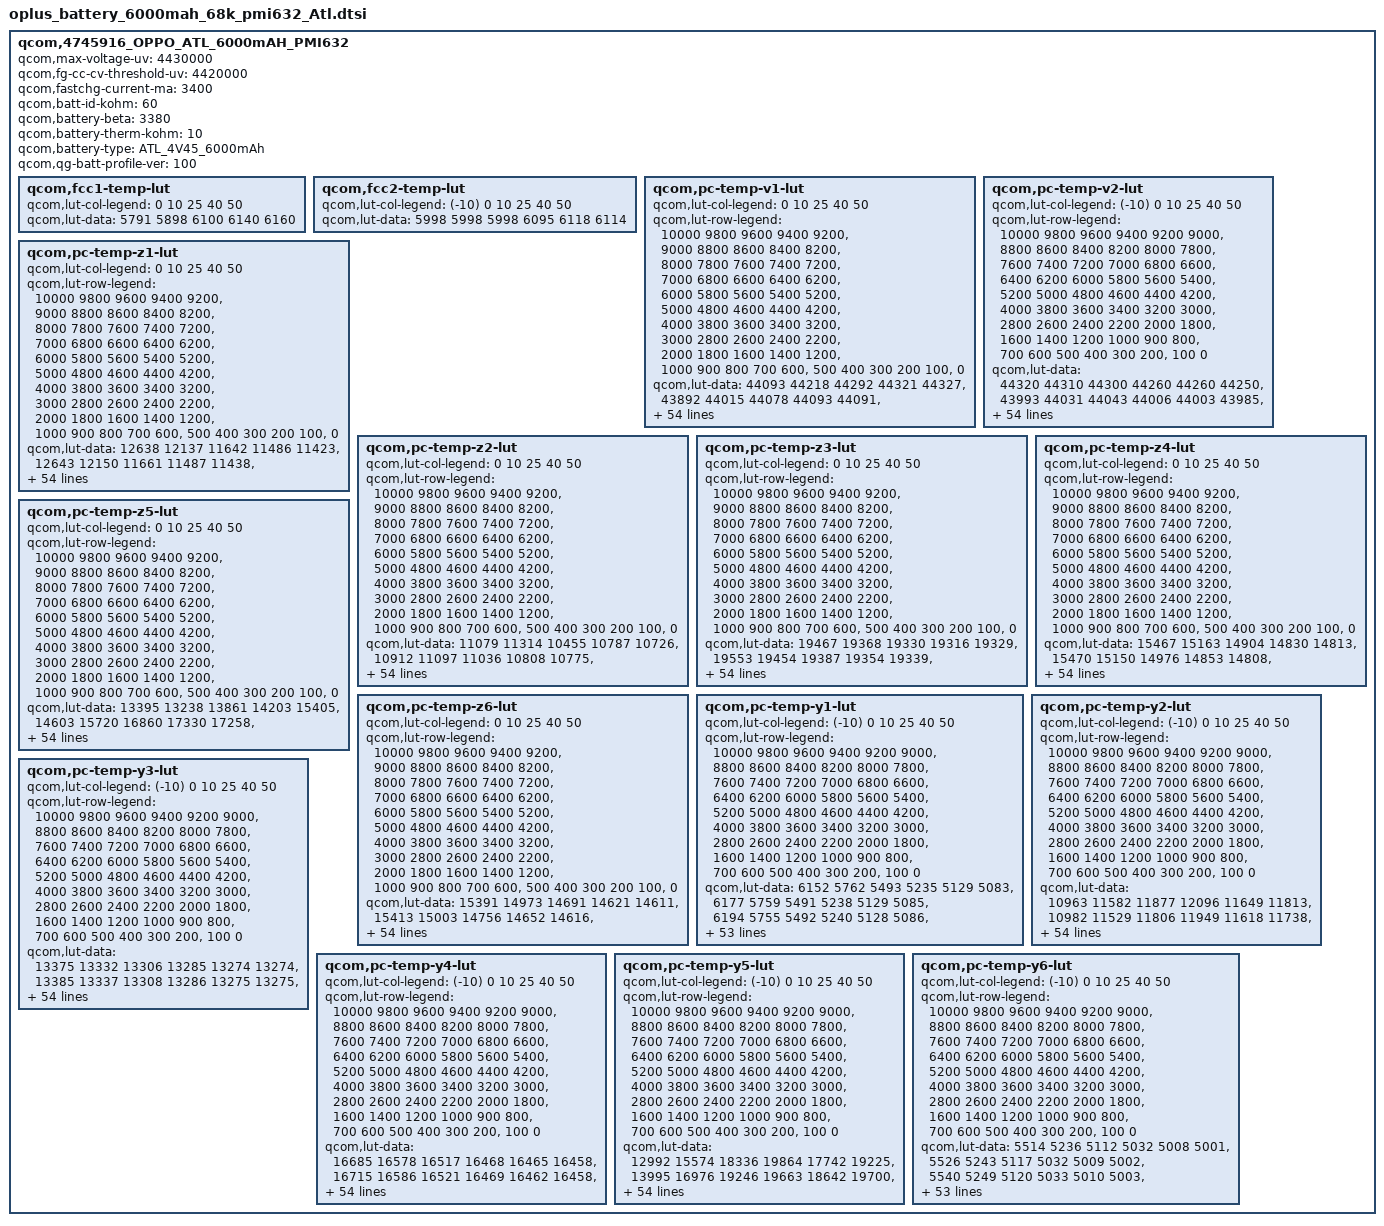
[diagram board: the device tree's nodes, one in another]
qcom,4745916_OPPO_ATL_6000mAH_PMI632 {
    /* 4745916_Wingtech_s88635_NVT_6000mAH_PMI632_averaged_MasterSlave_Aug20th2020 */
    qcom,max-voltage-uv = <4430000>;
    qcom,fg-cc-cv-threshold-uv = <4420000>;
    qcom,fastchg-current-ma = <3400>;
    //qcom,batt-id-kohm = <68>;
    qcom,batt-id-kohm = <60>;
    qcom,battery-beta = <3380>;
    qcom,battery-therm-kohm = <10>;
    qcom,battery-type = "ATL_4V45_6000mAh";
    qcom,qg-batt-profile-ver = <100>;
    //qcom,jeita-soft-thresholds_oppo = <0x5E68 0x72A>;
    //qcom,jeita-hard-thresholds_oppo = <0x5E68 0x72A>;

	qcom,fcc1-temp-lut {
		qcom,lut-col-legend = <0 10 25 40 50>;
		qcom,lut-data = <5791 5898 6100 6140 6160>;
	};

	qcom,fcc2-temp-lut {
		qcom,lut-col-legend = <(-10) 0 10 25 40 50>;
		qcom,lut-data = <5998 5998 5998 6095 6118 6114>;
	};

	qcom,pc-temp-v1-lut {
		qcom,lut-col-legend = <0 10 25 40 50>;
		qcom,lut-row-legend = <10000 9800 9600 9400 9200>,
			<9000 8800 8600 8400 8200>,
			<8000 7800 7600 7400 7200>,
			<7000 6800 6600 6400 6200>,
			<6000 5800 5600 5400 5200>,
			<5000 4800 4600 4400 4200>,
			<4000 3800 3600 3400 3200>,
			<3000 2800 2600 2400 2200>,
			<2000 1800 1600 1400 1200>,
			<1000 900 800 700 600>,
			<500 400 300 200 100>,
			<0>;
		qcom,lut-data = <44093 44218 44292 44321 44327>,
			<43892 44015 44078 44093 44091>,
			<43673 43805 43877 43887 43880>,
			<43445 43590 43671 43683 43676>,
			<43211 43368 43451 43467 43462>,
			<42968 43135 43218 43239 43236>,
			<42724 42893 42979 43005 43003>,
			<42482 42649 42733 42762 42763>,
			<42240 42403 42482 42513 42516>,
			<42002 42158 42233 42266 42270>,
			<41770 41919 41985 42018 42025>,
			<41542 41683 41741 41774 41782>,
			<41321 41454 41502 41535 41541>,
			<41107 41231 41269 41300 41303>,
			<40897 41014 41044 41073 41073>,
			<40690 40803 40826 40852 40849>,
			<40489 40598 40618 40640 40636>,
			<40299 40403 40417 40436 40434>,
			<40116 40224 40226 40242 40243>,
			<39942 40050 40054 40062 40063>,
			<39785 39870 39884 39894 39895>,
			<39629 39688 39659 39688 39695>,
			<39437 39491 39352 39396 39404>,
			<39188 39235 39101 39133 39131>,
			<38968 38968 38955 38982 38983>,
			<38822 38813 38842 38869 38879>,
			<38706 38725 38737 38761 38774>,
			<38621 38651 38642 38657 38665>,
			<38559 38572 38553 38561 38560>,
			<38507 38497 38470 38466 38460>,
			<38454 38427 38393 38377 38367>,
			<38404 38356 38321 38298 38285>,
			<38355 38293 38253 38227 38212>,
			<38306 38239 38192 38160 38143>,
			<38260 38192 38139 38096 38074>,
			<38218 38148 38089 38036 38008>,
			<38181 38111 38042 37980 37942>,
			<38138 38071 37998 37928 37880>,
			<38082 38017 37939 37863 37805>,
			<38012 37948 37852 37770 37705>,
			<37925 37864 37748 37661 37590>,
			<37806 37754 37634 37548 37472>,
			<37675 37626 37501 37422 37343>,
			<37532 37478 37339 37266 37189>,
			<37371 37317 37186 37122 37052>,
			<37223 37172 37081 37030 36968>,
			<37168 37121 37054 36997 36936>,
			<37124 37084 37031 36977 36916>,
			<37086 37062 37011 36953 36890>,
			<37046 37031 36956 36891 36808>,
			<36984 36990 36705 36630 36503>,
			<36791 36863 36250 36186 36045>,
			<35940 36433 35636 35600 35444>,
			<31626 35692 34766 34796 34617>,
			<30632 33115 33297 33531 33304>,
			<30000 30000 30000 30000 30000>;
	};

	qcom,pc-temp-v2-lut {
		qcom,lut-col-legend = <(-10) 0 10 25 40 50>;
		qcom,lut-row-legend = <10000 9800 9600 9400 9200 9000>,
			<8800 8600 8400 8200 8000 7800>,
			<7600 7400 7200 7000 6800 6600>,
			<6400 6200 6000 5800 5600 5400>,
			<5200 5000 4800 4600 4400 4200>,
			<4000 3800 3600 3400 3200 3000>,
			<2800 2600 2400 2200 2000 1800>,
			<1600 1400 1200 1000 900 800>,
			<700 600 500 400 300 200>,
			<100 0>;
		qcom,lut-data = <44320 44310 44300 44260 44260 44250>,
			<43993 44031 44043 44006 44003 43985>,
			<43694 43770 43799 43761 43757 43732>,
			<43429 43528 43568 43526 43524 43496>,
			<43196 43308 43352 43304 43305 43276>,
			<42965 43085 43132 43075 43079 43051>,
			<42719 42843 42893 42830 42839 42811>,
			<42470 42595 42646 42581 42592 42566>,
			<42223 42348 42399 42332 42345 42319>,
			<41979 42100 42152 42084 42095 42070>,
			<41733 41857 41907 41838 41848 41824>,
			<41478 41618 41665 41595 41605 41581>,
			<41227 41385 41428 41356 41365 41342>,
			<41013 41162 41196 41122 41131 41109>,
			<40837 40949 40971 40893 40903 40882>,
			<40634 40739 40753 40674 40683 40663>,
			<40326 40530 40541 40463 40473 40450>,
			<39977 40319 40334 40261 40270 40247>,
			<39711 40086 40138 40074 40083 40060>,
			<39499 39824 39956 39895 39902 39882>,
			<39303 39571 39756 39689 39699 39683>,
			<39112 39336 39502 39432 39467 39454>,
			<38930 39117 39232 39181 39237 39228>,
			<38755 38928 39016 38977 39024 39019>,
			<38583 38762 38836 38797 38826 38825>,
			<38435 38612 38681 38649 38672 38672>,
			<38316 38476 38549 38527 38550 38549>,
			<38216 38352 38433 38419 38441 38439>,
			<38134 38242 38325 38317 38340 38336>,
			<38067 38141 38224 38223 38246 38242>,
			<38006 38054 38133 38137 38163 38157>,
			<37948 37976 38049 38060 38088 38081>,
			<37893 37909 37973 37987 38016 38007>,
			<37836 37859 37906 37922 37949 37938>,
			<37779 37824 37848 37859 37880 37865>,
			<37720 37788 37796 37790 37796 37770>,
			<37657 37751 37752 37717 37698 37652>,
			<37592 37711 37712 37641 37600 37543>,
			<37518 37663 37659 37563 37507 37449>,
			<37437 37605 37593 37482 37415 37359>,
			<37348 37529 37515 37394 37331 37274>,
			<37246 37403 37421 37298 37245 37188>,
			<37137 37250 37306 37175 37117 37058>,
			<37028 37099 37168 37037 36982 36925>,
			<36919 36938 37010 36914 36877 36819>,
			<36808 36796 36864 36863 36831 36782>,
			<36754 36748 36818 36841 36819 36769>,
			<36695 36702 36776 36821 36803 36749>,
			<36610 36656 36745 36782 36767 36711>,
			<37099 36596 36686 36658 36646 36565>,
			<37944 36535 36601 36320 36286 36193>,
			<37349 36786 36419 35770 35760 35658>,
			<31698 37119 36004 35009 35060 34955>,
			<30995 31207 35383 33808 34062 33935>,
			<30139 30334 33146 32016 32441 32316>,
			<29008 29322 29643 27350 29483 27639>;
	};

	qcom,pc-temp-z1-lut {
		qcom,lut-col-legend = <0 10 25 40 50>;
		qcom,lut-row-legend = <10000 9800 9600 9400 9200>,
			<9000 8800 8600 8400 8200>,
			<8000 7800 7600 7400 7200>,
			<7000 6800 6600 6400 6200>,
			<6000 5800 5600 5400 5200>,
			<5000 4800 4600 4400 4200>,
			<4000 3800 3600 3400 3200>,
			<3000 2800 2600 2400 2200>,
			<2000 1800 1600 1400 1200>,
			<1000 900 800 700 600>,
			<500 400 300 200 100>,
			<0>;
		qcom,lut-data = <12638 12137 11642 11486 11423>,
			<12643 12150 11661 11487 11438>,
			<12649 12152 11669 11487 11437>,
			<12655 12147 11676 11488 11437>,
			<12654 12141 11675 11488 11437>,
			<12643 12136 11670 11487 11438>,
			<12636 12129 11668 11486 11439>,
			<12638 12123 11669 11487 11440>,
			<12640 12117 11669 11488 11444>,
			<12637 12111 11668 11490 11448>,
			<12629 12108 11663 11492 11453>,
			<12621 12106 11662 11494 11458>,
			<12614 12103 11665 11498 11463>,
			<12601 12101 11669 11501 11468>,
			<12592 12098 11672 11505 11472>,
			<12579 12097 11675 11509 11477>,
			<12565 12099 11679 11514 11481>,
			<12559 12101 11684 11518 11486>,
			<12556 12100 11688 11522 11490>,
			<12554 12099 11692 11527 11495>,
			<12550 12099 11696 11531 11501>,
			<12544 12100 11699 11534 11505>,
			<12544 12102 11704 11537 11508>,
			<12551 12106 11708 11539 11511>,
			<12557 12112 11713 11542 11514>,
			<12560 12118 11718 11546 11517>,
			<12565 12126 11723 11550 11521>,
			<12568 12131 11728 11553 11525>,
			<12571 12132 11733 11557 11529>,
			<12573 12132 11737 11561 11533>,
			<12574 12133 11741 11565 11536>,
			<12574 12136 11745 11569 11540>,
			<12575 12140 11750 11573 11543>,
			<12583 12142 11754 11577 11547>,
			<12593 12144 11759 11580 11551>,
			<12598 12147 11764 11583 11554>,
			<12602 12149 11767 11586 11557>,
			<12607 12152 11769 11590 11560>,
			<12615 12157 11772 11593 11562>,
			<12626 12166 11779 11595 11564>,
			<12633 12175 11785 11598 11566>,
			<12642 12184 11789 11601 11568>,
			<12650 12195 11793 11603 11571>,
			<12666 12210 11802 11606 11573>,
			<12694 12213 11808 11611 11575>,
			<12676 12210 11814 11613 11577>,
			<12680 12222 11814 11613 11577>,
			<12677 12213 11815 11614 11578>,
			<12682 12209 11823 11616 11580>,
			<12683 12218 11827 11619 11582>,
			<12682 12220 11830 11625 11586>,
			<12701 12226 11838 11629 11591>,
			<12718 12232 11851 11638 11598>,
			<12694 12237 11869 11650 11608>,
			<12694 12237 11869 11650 11608>,
			<12694 12237 11869 11650 11608>;
	};

	qcom,pc-temp-z2-lut {
		qcom,lut-col-legend = <0 10 25 40 50>;
		qcom,lut-row-legend = <10000 9800 9600 9400 9200>,
			<9000 8800 8600 8400 8200>,
			<8000 7800 7600 7400 7200>,
			<7000 6800 6600 6400 6200>,
			<6000 5800 5600 5400 5200>,
			<5000 4800 4600 4400 4200>,
			<4000 3800 3600 3400 3200>,
			<3000 2800 2600 2400 2200>,
			<2000 1800 1600 1400 1200>,
			<1000 900 800 700 600>,
			<500 400 300 200 100>,
			<0>;
		qcom,lut-data = <11079 11314 10455 10787 10726>,
			<10912 11097 11036 10808 10775>,
			<10839 10992 11013 10937 10981>,
			<10788 10953 10982 10984 11019>,
			<10749 10926 10969 10987 11025>,
			<10716 10895 10950 10952 10985>,
			<10695 10865 10929 10910 10931>,
			<10684 10848 10898 10879 10893>,
			<10677 10838 10864 10851 10860>,
			<10676 10832 10836 10829 10821>,
			<10680 10833 10810 10810 10768>,
			<10686 10835 10805 10801 10737>,
			<10696 10840 10829 10814 10765>,
			<10713 10856 10860 10836 10825>,
			<10730 10882 10884 10854 10874>,
			<10745 10911 10908 10878 10920>,
			<10762 10949 10935 10906 10947>,
			<10793 10983 10971 10944 10957>,
			<10842 11014 11001 10981 10964>,
			<10889 11038 11016 11004 10965>,
			<10932 11038 11028 11020 10964>,
			<10966 11017 11067 11068 11004>,
			<10972 11003 11187 11335 11407>,
			<10968 11015 11258 11560 11806>,
			<10966 11037 11171 11408 11634>,
			<10966 11043 11043 11083 11146>,
			<10967 11041 11033 11019 11021>,
			<10969 11040 11081 11164 11335>,
			<10976 11047 11115 11277 11594>,
			<10985 11061 11126 11291 11527>,
			<10994 11065 11134 11291 11365>,
			<11006 11061 11139 11259 11223>,
			<11015 11057 11140 11153 11064>,
			<11021 11058 11138 11082 10982>,
			<11026 11063 11115 11066 10979>,
			<11033 11069 11093 11063 10984>,
			<11040 11077 11111 11095 11024>,
			<11048 11088 11171 11188 11163>,
			<11061 11103 11218 11277 11295>,
			<11077 11122 11252 11364 11416>,
			<11095 11140 11275 11422 11498>,
			<11117 11155 11285 11407 11485>,
			<11148 11176 11290 11368 11439>,
			<11212 11217 11296 11349 11411>,
			<11135 11538 11352 11347 11364>,
			<10997 11715 11414 11189 11111>,
			<10996 11726 11374 11195 11105>,
			<10840 11729 11350 11207 11141>,
			<10694 12189 11466 11192 11255>,
			<10433 12217 11742 11381 11268>,
			<10456 12182 11709 11241 11024>,
			<10308 11894 11417 10934 10748>,
			<11440 11516 11215 10804 10662>,
			<11525 11230 11003 10661 10586>,
			<11525 11230 11003 10661 10586>,
			<11525 11230 11003 10661 10586>;
	};

	qcom,pc-temp-z3-lut {
		qcom,lut-col-legend = <0 10 25 40 50>;
		qcom,lut-row-legend = <10000 9800 9600 9400 9200>,
			<9000 8800 8600 8400 8200>,
			<8000 7800 7600 7400 7200>,
			<7000 6800 6600 6400 6200>,
			<6000 5800 5600 5400 5200>,
			<5000 4800 4600 4400 4200>,
			<4000 3800 3600 3400 3200>,
			<3000 2800 2600 2400 2200>,
			<2000 1800 1600 1400 1200>,
			<1000 900 800 700 600>,
			<500 400 300 200 100>,
			<0>;
		qcom,lut-data = <19467 19368 19330 19316 19329>,
			<19553 19454 19387 19354 19339>,
			<19611 19498 19404 19373 19363>,
			<19652 19519 19415 19383 19373>,
			<19674 19530 19426 19393 19381>,
			<19689 19533 19436 19402 19389>,
			<19695 19535 19441 19407 19395>,
			<19694 19535 19442 19408 19396>,
			<19691 19534 19443 19409 19397>,
			<19689 19533 19442 19409 19397>,
			<19687 19531 19440 19408 19394>,
			<19685 19528 19437 19406 19391>,
			<19680 19524 19432 19400 19388>,
			<19672 19520 19426 19392 19385>,
			<19669 19516 19420 19387 19382>,
			<19671 19512 19414 19382 19379>,
			<19674 19509 19409 19378 19375>,
			<19669 19505 19404 19374 19369>,
			<19650 19498 19399 19370 19361>,
			<19639 19492 19394 19363 19353>,
			<19637 19492 19390 19355 19345>,
			<19637 19498 19393 19354 19343>,
			<19640 19506 19415 19368 19354>,
			<19657 19516 19429 19381 19365>,
			<19671 19526 19418 19370 19356>,
			<19669 19526 19399 19347 19332>,
			<19663 19513 19393 19341 19325>,
			<19656 19501 19389 19342 19342>,
			<19649 19501 19388 19343 19358>,
			<19641 19500 19391 19356 19368>,
			<19637 19501 19397 19375 19379>,
			<19633 19507 19404 19379 19380>,
			<19630 19513 19413 19378 19373>,
			<19628 19512 19416 19376 19365>,
			<19627 19508 19414 19372 19356>,
			<19625 19505 19410 19366 19348>,
			<19623 19503 19406 19359 19341>,
			<19620 19500 19400 19351 19336>,
			<19614 19496 19396 19348 19334>,
			<19606 19492 19393 19350 19335>,
			<19597 19486 19390 19351 19336>,
			<19586 19480 19388 19351 19340>,
			<19559 19472 19385 19351 19346>,
			<19438 19460 19380 19352 19349>,
			<19324 19418 19370 19351 19348>,
			<19298 19398 19362 19332 19329>,
			<19296 19393 19351 19330 19324>,
			<19294 19389 19350 19323 19315>,
			<19289 19285 19330 19318 19309>,
			<19277 19280 19306 19311 19313>,
			<19277 19279 19316 19343 19336>,
			<19296 19285 19330 19357 19343>,
			<19456 19358 19357 19357 19343>,
			<19285 19425 19378 19354 19343>,
			<19285 19425 19378 19354 19343>,
			<19285 19425 19378 19354 19343>;
	};

	qcom,pc-temp-z4-lut {
		qcom,lut-col-legend = <0 10 25 40 50>;
		qcom,lut-row-legend = <10000 9800 9600 9400 9200>,
			<9000 8800 8600 8400 8200>,
			<8000 7800 7600 7400 7200>,
			<7000 6800 6600 6400 6200>,
			<6000 5800 5600 5400 5200>,
			<5000 4800 4600 4400 4200>,
			<4000 3800 3600 3400 3200>,
			<3000 2800 2600 2400 2200>,
			<2000 1800 1600 1400 1200>,
			<1000 900 800 700 600>,
			<500 400 300 200 100>,
			<0>;
		qcom,lut-data = <15467 15163 14904 14830 14813>,
			<15470 15150 14976 14853 14808>,
			<15399 15124 14955 14856 14827>,
			<15293 15069 14921 14837 14813>,
			<15210 15006 14890 14818 14797>,
			<15133 14962 14858 14797 14780>,
			<15070 14925 14831 14777 14763>,
			<15023 14893 14808 14761 14748>,
			<14984 14865 14787 14746 14735>,
			<14949 14841 14769 14732 14722>,
			<14918 14821 14753 14718 14711>,
			<14892 14804 14739 14707 14701>,
			<14872 14789 14724 14700 14693>,
			<14856 14775 14713 14694 14685>,
			<14839 14763 14708 14689 14680>,
			<14817 14751 14704 14684 14676>,
			<14801 14740 14701 14679 14672>,
			<14800 14733 14698 14674 14670>,
			<14801 14731 14695 14670 14667>,
			<14801 14729 14691 14669 14665>,
			<14781 14727 14689 14668 14662>,
			<14752 14724 14696 14671 14663>,
			<14751 14723 14739 14713 14707>,
			<14782 14753 14776 14759 14758>,
			<14812 14806 14793 14778 14774>,
			<14827 14819 14804 14791 14783>,
			<14838 14815 14804 14793 14782>,
			<14840 14810 14796 14782 14755>,
			<14832 14801 14785 14766 14724>,
			<14821 14787 14771 14741 14702>,
			<14811 14773 14753 14711 14681>,
			<14800 14759 14735 14695 14672>,
			<14790 14747 14715 14683 14667>,
			<14781 14739 14705 14678 14666>,
			<14772 14734 14700 14677 14666>,
			<14764 14729 14698 14677 14668>,
			<14756 14724 14697 14677 14668>,
			<14749 14719 14697 14678 14667>,
			<14740 14715 14697 14679 14668>,
			<14730 14711 14701 14684 14675>,
			<14721 14706 14705 14690 14684>,
			<14711 14698 14702 14688 14680>,
			<14715 14690 14694 14681 14669>,
			<14812 14680 14690 14679 14666>,
			<14847 14670 14679 14669 14659>,
			<14855 14670 14659 14661 14651>,
			<14854 14672 14659 14658 14649>,
			<14854 14672 14648 14651 14644>,
			<14855 14781 14658 14638 14631>,
			<14860 14781 14680 14638 14620>,
			<14860 14780 14690 14631 14634>,
			<14852 14776 14684 14632 14640>,
			<14832 14720 14658 14636 14646>,
			<16713 14703 14646 14644 14652>,
			<16713 14703 14646 14644 14652>,
			<16713 14703 14646 14644 14652>;
	};

	qcom,pc-temp-z5-lut {
		qcom,lut-col-legend = <0 10 25 40 50>;
		qcom,lut-row-legend = <10000 9800 9600 9400 9200>,
			<9000 8800 8600 8400 8200>,
			<8000 7800 7600 7400 7200>,
			<7000 6800 6600 6400 6200>,
			<6000 5800 5600 5400 5200>,
			<5000 4800 4600 4400 4200>,
			<4000 3800 3600 3400 3200>,
			<3000 2800 2600 2400 2200>,
			<2000 1800 1600 1400 1200>,
			<1000 900 800 700 600>,
			<500 400 300 200 100>,
			<0>;
		qcom,lut-data = <13395 13238 13861 14203 15405>,
			<14603 15720 16860 17330 17258>,
			<15697 17156 17659 18995 19934>,
			<16676 17930 18195 20073 21256>,
			<17463 18451 18832 21096 22496>,
			<18133 18801 19577 22097 23858>,
			<18694 19048 20100 22951 25074>,
			<19126 19357 20485 23585 26028>,
			<19519 19807 20889 24144 26833>,
			<20041 20319 21370 24908 27489>,
			<20805 20839 21991 25969 27958>,
			<21586 21428 22715 26757 28560>,
			<22180 22057 23712 27146 29998>,
			<22759 22692 24509 27332 32129>,
			<23711 23444 24824 27452 34093>,
			<26440 24706 25006 27990 36186>,
			<28995 26818 25086 28602 37131>,
			<28928 27926 25375 29793 36255>,
			<27743 27434 25714 30841 34933>,
			<27089 26696 25976 30445 34032>,
			<29132 27288 26390 29216 32665>,
			<33704 31904 30026 29518 32725>,
			<40692 37395 46948 38994 39701>,
			<54752 42852 57567 47391 46680>,
			<64253 47922 47159 40420 40639>,
			<61632 47859 30947 25257 24512>,
			<54918 39111 25763 20274 19359>,
			<49498 31673 23567 19330 21016>,
			<44938 30722 22852 18974 23281>,
			<41762 30248 23317 21053 27230>,
			<40954 30432 24344 25068 32746>,
			<40532 33752 26595 27739 34461>,
			<40413 37670 31386 29907 34469>,
			<41403 39728 35195 31670 34043>,
			<43031 41290 38148 33375 33138>,
			<44202 42176 40054 34615 32085>,
			<45269 42918 39899 34106 31599>,
			<45910 43432 38993 31946 31302>,
			<45984 43291 38022 31012 31098>,
			<45794 42650 36301 31461 30906>,
			<45232 41985 34257 31927 30820>,
			<43008 40319 32217 30631 31220>,
			<38545 38285 30148 28096 32441>,
			<25627 35924 28581 28875 35251>,
			<15587 31317 28570 30192 37060>,
			<13431 27931 29987 24301 26494>,
			<13337 26072 25427 23337 23690>,
			<13179 25568 26406 21923 21712>,
			<12935 13141 19869 23523 23900>,
			<12696 12915 15762 21518 29288>,
			<12682 12861 16286 35648 36550>,
			<13902 13323 16850 36187 33343>,
			<27073 20549 21459 32062 28593>,
			<11344 29268 27669 25459 23605>,
			<11344 29268 27669 25459 23605>,
			<11344 29268 27669 25459 23605>;
	};

	qcom,pc-temp-z6-lut {
		qcom,lut-col-legend = <0 10 25 40 50>;
		qcom,lut-row-legend = <10000 9800 9600 9400 9200>,
			<9000 8800 8600 8400 8200>,
			<8000 7800 7600 7400 7200>,
			<7000 6800 6600 6400 6200>,
			<6000 5800 5600 5400 5200>,
			<5000 4800 4600 4400 4200>,
			<4000 3800 3600 3400 3200>,
			<3000 2800 2600 2400 2200>,
			<2000 1800 1600 1400 1200>,
			<1000 900 800 700 600>,
			<500 400 300 200 100>,
			<0>;
		qcom,lut-data = <15391 14973 14691 14621 14611>,
			<15413 15003 14756 14652 14616>,
			<15392 15009 14753 14658 14633>,
			<15357 14990 14747 14658 14634>,
			<15324 14964 14740 14657 14634>,
			<15287 14943 14731 14653 14631>,
			<15252 14923 14721 14647 14627>,
			<15223 14905 14712 14642 14623>,
			<15197 14889 14702 14636 14619>,
			<15174 14874 14694 14630 14614>,
			<15154 14862 14686 14625 14609>,
			<15137 14850 14678 14619 14604>,
			<15120 14840 14669 14613 14599>,
			<15104 14830 14661 14607 14595>,
			<15091 14821 14656 14602 14591>,
			<15080 14813 14652 14598 14588>,
			<15070 14806 14648 14594 14585>,
			<15059 14800 14644 14590 14581>,
			<15050 14795 14641 14587 14576>,
			<15040 14792 14637 14583 14572>,
			<15027 14791 14635 14579 14567>,
			<15016 14794 14640 14580 14566>,
			<15018 14798 14674 14608 14593>,
			<15042 14818 14695 14634 14621>,
			<15062 14847 14694 14633 14621>,
			<15067 14853 14693 14630 14615>,
			<15070 14847 14691 14627 14610>,
			<15070 14840 14686 14623 14607>,
			<15064 14835 14682 14619 14605>,
			<15056 14830 14678 14616 14602>,
			<15050 14826 14675 14613 14599>,
			<15044 14824 14672 14610 14596>,
			<15040 14822 14669 14605 14591>,
			<15036 14820 14666 14602 14586>,
			<15033 14817 14664 14599 14583>,
			<15030 14814 14662 14597 14579>,
			<15029 14812 14659 14594 14576>,
			<15027 14810 14657 14590 14573>,
			<15026 14809 14656 14589 14572>,
			<15025 14808 14657 14592 14576>,
			<15023 14807 14659 14595 14580>,
			<15021 14804 14657 14594 14580>,
			<15017 14800 14654 14592 14579>,
			<15009 14794 14651 14592 14579>,
			<14976 14774 14643 14588 14576>,
			<14969 14767 14633 14575 14563>,
			<14968 14766 14628 14573 14560>,
			<14967 14763 14623 14566 14553>,
			<14967 14758 14616 14558 14544>,
			<14967 14756 14616 14554 14542>,
			<14972 14757 14627 14569 14561>,
			<14985 14763 14635 14579 14569>,
			<15069 14781 14641 14582 14574>,
			<15803 14814 14653 14588 14580>,
			<15803 14814 14653 14588 14580>,
			<15803 14814 14653 14588 14580>;
	};

	qcom,pc-temp-y1-lut {
		qcom,lut-col-legend = <(-10) 0 10 25 40 50>;
		qcom,lut-row-legend = <10000 9800 9600 9400 9200 9000>,
			<8800 8600 8400 8200 8000 7800>,
			<7600 7400 7200 7000 6800 6600>,
			<6400 6200 6000 5800 5600 5400>,
			<5200 5000 4800 4600 4400 4200>,
			<4000 3800 3600 3400 3200 3000>,
			<2800 2600 2400 2200 2000 1800>,
			<1600 1400 1200 1000 900 800>,
			<700 600 500 400 300 200>,
			<100 0>;
		qcom,lut-data = <6152 5762 5493 5235 5129 5083>,
			<6177 5759 5491 5238 5129 5085>,
			<6194 5755 5492 5240 5128 5086>,
			<6205 5751 5492 5241 5128 5088>,
			<6212 5748 5493 5241 5128 5090>,
			<6216 5746 5494 5241 5128 5091>,
			<6215 5746 5496 5239 5128 5093>,
			<6210 5747 5499 5237 5128 5095>,
			<6207 5748 5498 5238 5128 5097>,
			<6197 5749 5492 5240 5129 5100>,
			<6190 5750 5488 5242 5129 5102>,
			<6195 5750 5488 5242 5130 5103>,
			<6202 5751 5488 5242 5130 5104>,
			<6208 5752 5489 5243 5131 5105>,
			<6211 5755 5491 5245 5132 5108>,
			<6215 5757 5492 5246 5133 5111>,
			<6222 5757 5491 5248 5135 5113>,
			<6229 5757 5488 5251 5137 5116>,
			<6230 5758 5489 5254 5139 5117>,
			<6225 5761 5492 5257 5141 5119>,
			<6221 5764 5494 5259 5143 5121>,
			<6219 5768 5495 5262 5144 5122>,
			<6221 5774 5495 5264 5146 5124>,
			<6227 5776 5496 5267 5148 5125>,
			<6239 5776 5497 5269 5150 5127>,
			<6246 5777 5498 5272 5152 5129>,
			<6239 5778 5503 5274 5153 5131>,
			<6225 5781 5509 5275 5154 5133>,
			<6217 5782 5510 5277 5157 5135>,
			<6211 5785 5509 5279 5160 5136>,
			<6207 5786 5508 5281 5162 5138>,
			<6212 5786 5509 5286 5164 5141>,
			<6219 5786 5510 5291 5166 5143>,
			<6219 5784 5511 5295 5169 5144>,
			<6212 5778 5513 5298 5171 5145>,
			<6210 5774 5515 5298 5172 5146>,
			<6214 5776 5518 5298 5172 5149>,
			<6218 5781 5523 5298 5172 5151>,
			<6216 5780 5525 5298 5174 5151>,
			<6201 5775 5527 5299 5175 5150>,
			<6191 5771 5527 5300 5176 5151>,
			<6202 5776 5528 5302 5177 5152>,
			<6214 5782 5529 5305 5178 5154>,
			<6211 5784 5530 5308 5180 5155>,
			<6220 5786 5529 5312 5181 5157>,
			<6233 5790 5533 5314 5185 5158>,
			<6227 5795 5544 5313 5184 5159>,
			<6233 5794 5538 5315 5184 5160>,
			<6275 5804 5547 5317 5185 5160>,
			<6256 5812 5546 5318 5185 5161>,
			<6310 5815 5557 5322 5187 5161>,
			<6334 5840 5546 5334 5191 5165>,
			<6421 5877 5568 5349 5196 5171>,
			<6448 5927 5593 5374 5206 5179>,
			<6448 5927 5593 5374 5206 5179>,
			<6448 5927 5593 5374 5206 5179>;
	};

	qcom,pc-temp-y2-lut {
		qcom,lut-col-legend = <(-10) 0 10 25 40 50>;
		qcom,lut-row-legend = <10000 9800 9600 9400 9200 9000>,
			<8800 8600 8400 8200 8000 7800>,
			<7600 7400 7200 7000 6800 6600>,
			<6400 6200 6000 5800 5600 5400>,
			<5200 5000 4800 4600 4400 4200>,
			<4000 3800 3600 3400 3200 3000>,
			<2800 2600 2400 2200 2000 1800>,
			<1600 1400 1200 1000 900 800>,
			<700 600 500 400 300 200>,
			<100 0>;
		qcom,lut-data = <10963 11582 11877 12096 11649 11813>,
			<10982 11529 11806 11949 11618 11738>,
			<11007 11479 11735 11817 11563 11647>,
			<11032 11433 11668 11706 11502 11553>,
			<11051 11391 11610 11624 11452 11470>,
			<11059 11356 11566 11577 11432 11412>,
			<11056 11323 11534 11567 11430 11361>,
			<11051 11298 11508 11575 11428 11322>,
			<11053 11289 11487 11567 11409 11312>,
			<11070 11285 11465 11535 11351 11288>,
			<11091 11283 11454 11519 11319 11268>,
			<11111 11297 11461 11501 11320 11247>,
			<11134 11324 11474 11483 11330 11231>,
			<11174 11346 11487 11499 11339 11253>,
			<11249 11367 11502 11542 11355 11316>,
			<11291 11389 11524 11587 11381 11350>,
			<11289 11421 11570 11630 11435 11344>,
			<11285 11453 11628 11677 11501 11340>,
			<11233 11461 11662 11734 11560 11382>,
			<10976 11461 11684 11797 11621 11475>,
			<10812 11463 11699 11824 11712 11589>,
			<11000 11510 11708 11829 11875 11771>,
			<11287 11589 11716 11835 11977 11903>,
			<11278 11632 11731 11857 11910 11928>,
			<10920 11656 11764 11892 11792 11931>,
			<10649 11682 11799 11918 11776 11923>,
			<10324 11728 11832 11945 11819 11881>,
			<9871 11775 11866 11970 11867 11865>,
			<9760 11784 11890 11989 11898 11964>,
			<9743 11781 11910 12006 11930 12099>,
			<9731 11780 11921 12026 11990 12139>,
			<9719 11854 11922 12077 12091 12156>,
			<9709 11965 11920 12107 12158 12178>,
			<9701 11957 11920 12086 12195 12231>,
			<9693 11784 11919 12053 12220 12279>,
			<9687 11620 11914 12041 12203 12247>,
			<9683 11541 11895 12035 12136 12115>,
			<9680 11476 11862 12027 12076 12006>,
			<9676 11402 11822 11978 11998 11912>,
			<9673 11326 11764 11915 11933 11848>,
			<9671 11199 11694 11899 11934 11886>,
			<9670 10500 11606 11905 11949 11969>,
			<9669 9820 11507 11897 11919 11918>,
			<9667 9735 11410 11874 11850 11767>,
			<9666 9699 11277 11833 11721 11628>,
			<9664 9683 11143 11687 11541 11474>,
			<9668 9676 11013 11641 11529 11401>,
			<9696 9671 10168 11598 11554 11483>,
			<9781 9666 10331 11591 11566 11552>,
			<9666 9663 9974 11574 11519 11428>,
			<9657 9706 9737 11483 11462 11304>,
			<9652 9677 9673 11301 11345 11222>,
			<9654 9660 9684 11060 11216 11148>,
			<9652 9656 9884 10528 11030 10893>,
			<9652 9656 9884 10528 11030 10893>,
			<9652 9656 9884 10528 11030 10893>;
	};

	qcom,pc-temp-y3-lut {
		qcom,lut-col-legend = <(-10) 0 10 25 40 50>;
		qcom,lut-row-legend = <10000 9800 9600 9400 9200 9000>,
			<8800 8600 8400 8200 8000 7800>,
			<7600 7400 7200 7000 6800 6600>,
			<6400 6200 6000 5800 5600 5400>,
			<5200 5000 4800 4600 4400 4200>,
			<4000 3800 3600 3400 3200 3000>,
			<2800 2600 2400 2200 2000 1800>,
			<1600 1400 1200 1000 900 800>,
			<700 600 500 400 300 200>,
			<100 0>;
		qcom,lut-data = <13375 13332 13306 13285 13274 13274>,
			<13385 13337 13308 13286 13275 13275>,
			<13401 13343 13311 13286 13277 13275>,
			<13417 13349 13314 13285 13279 13276>,
			<13431 13354 13317 13285 13280 13277>,
			<13438 13357 13318 13285 13280 13277>,
			<13440 13358 13318 13284 13280 13277>,
			<13442 13359 13317 13284 13280 13278>,
			<13441 13360 13317 13285 13280 13278>,
			<13440 13361 13318 13290 13281 13279>,
			<13439 13362 13318 13292 13282 13280>,
			<13439 13361 13318 13292 13282 13280>,
			<13438 13360 13318 13292 13282 13280>,
			<13437 13361 13318 13292 13282 13280>,
			<13432 13362 13320 13291 13282 13281>,
			<13426 13363 13321 13292 13282 13281>,
			<13418 13363 13320 13294 13285 13281>,
			<13409 13361 13320 13297 13288 13281>,
			<13399 13359 13320 13297 13289 13282>,
			<13382 13354 13323 13298 13290 13285>,
			<13371 13350 13325 13298 13290 13286>,
			<13374 13345 13322 13296 13288 13284>,
			<13379 13341 13316 13293 13285 13281>,
			<13373 13337 13311 13289 13281 13279>,
			<13353 13334 13307 13286 13277 13276>,
			<13341 13330 13305 13285 13276 13275>,
			<13339 13325 13305 13285 13276 13275>,
			<13339 13320 13305 13285 13276 13275>,
			<13340 13319 13305 13285 13275 13275>,
			<13347 13320 13304 13285 13274 13274>,
			<13355 13320 13303 13285 13275 13274>,
			<13363 13313 13303 13286 13275 13274>,
			<13374 13302 13303 13286 13276 13274>,
			<13387 13302 13304 13286 13277 13275>,
			<13405 13314 13304 13286 13278 13276>,
			<13427 13325 13305 13286 13278 13276>,
			<13454 13331 13306 13285 13278 13274>,
			<13487 13335 13307 13285 13277 13273>,
			<13528 13340 13307 13285 13277 13274>,
			<13579 13346 13308 13286 13276 13274>,
			<13639 13349 13308 13286 13278 13276>,
			<13704 13349 13310 13286 13281 13278>,
			<13785 13349 13313 13286 13280 13277>,
			<13900 13371 13315 13286 13278 13276>,
			<14072 13407 13318 13286 13278 13275>,
			<14289 13448 13316 13290 13282 13282>,
			<14547 13504 13317 13292 13286 13283>,
			<14886 13602 13312 13299 13290 13285>,
			<15167 13778 13330 13303 13291 13286>,
			<13734 14169 13345 13303 13289 13283>,
			<14333 14919 13404 13302 13287 13282>,
			<15852 13542 13610 13305 13287 13282>,
			<22816 13999 14559 13315 13291 13288>,
			<43390 16685 14216 13367 13298 13294>,
			<43390 16685 14216 13367 13298 13294>,
			<43390 16685 14216 13367 13298 13294>;
	};

	qcom,pc-temp-y4-lut {
		qcom,lut-col-legend = <(-10) 0 10 25 40 50>;
		qcom,lut-row-legend = <10000 9800 9600 9400 9200 9000>,
			<8800 8600 8400 8200 8000 7800>,
			<7600 7400 7200 7000 6800 6600>,
			<6400 6200 6000 5800 5600 5400>,
			<5200 5000 4800 4600 4400 4200>,
			<4000 3800 3600 3400 3200 3000>,
			<2800 2600 2400 2200 2000 1800>,
			<1600 1400 1200 1000 900 800>,
			<700 600 500 400 300 200>,
			<100 0>;
		qcom,lut-data = <16685 16578 16517 16468 16465 16458>,
			<16715 16586 16521 16469 16462 16458>,
			<16754 16602 16527 16472 16460 16458>,
			<16794 16620 16533 16477 16459 16458>,
			<16826 16635 16538 16481 16459 16458>,
			<16845 16641 16541 16484 16459 16459>,
			<16852 16640 16541 16487 16460 16459>,
			<16856 16639 16542 16491 16463 16459>,
			<16863 16640 16543 16490 16464 16459>,
			<16876 16642 16545 16488 16466 16460>,
			<16882 16646 16549 16487 16468 16460>,
			<16880 16657 16555 16492 16471 16463>,
			<16877 16675 16565 16500 16475 16466>,
			<16889 16694 16574 16507 16480 16469>,
			<16960 16718 16585 16516 16485 16472>,
			<17005 16741 16599 16525 16489 16475>,
			<16921 16764 16623 16533 16492 16481>,
			<16789 16782 16652 16543 16495 16487>,
			<16759 16776 16668 16564 16506 16495>,
			<16770 16722 16680 16594 16521 16503>,
			<16776 16665 16685 16600 16525 16504>,
			<16738 16624 16641 16564 16520 16502>,
			<16685 16590 16567 16521 16512 16497>,
			<16675 16570 16532 16495 16492 16482>,
			<16683 16557 16514 16475 16466 16460>,
			<16690 16551 16504 16471 16461 16456>,
			<16698 16549 16499 16472 16462 16456>,
			<16711 16548 16497 16473 16464 16457>,
			<16717 16544 16497 16477 16469 16461>,
			<16720 16533 16499 16483 16476 16467>,
			<16723 16526 16500 16489 16483 16474>,
			<16725 16540 16499 16494 16491 16481>,
			<16728 16561 16498 16499 16497 16488>,
			<16733 16564 16498 16503 16502 16494>,
			<16741 16558 16498 16506 16505 16498>,
			<16748 16554 16499 16504 16501 16493>,
			<16755 16564 16505 16493 16484 16476>,
			<16760 16584 16516 16483 16473 16467>,
			<16761 16601 16524 16479 16468 16466>,
			<16760 16616 16530 16476 16465 16465>,
			<16759 16630 16536 16478 16468 16470>,
			<16755 16649 16542 16486 16474 16479>,
			<16751 16660 16548 16486 16468 16470>,
			<16748 16658 16556 16480 16457 16454>,
			<16755 16653 16556 16471 16446 16444>,
			<16755 16644 16536 16478 16460 16465>,
			<16766 16649 16547 16492 16484 16497>,
			<16750 16657 16598 16512 16518 16532>,
			<16507 16677 16602 16546 16552 16566>,
			<21121 16711 16635 16550 16546 16543>,
			<24932 16763 16682 16525 16477 16481>,
			<34566 21027 16742 16525 16473 16476>,
			<20968 23981 16853 16557 16476 16475>,
			<37921 18169 18487 16663 16491 16481>,
			<37921 18169 18487 16663 16491 16481>,
			<37921 18169 18487 16663 16491 16481>;
	};

	qcom,pc-temp-y5-lut {
		qcom,lut-col-legend = <(-10) 0 10 25 40 50>;
		qcom,lut-row-legend = <10000 9800 9600 9400 9200 9000>,
			<8800 8600 8400 8200 8000 7800>,
			<7600 7400 7200 7000 6800 6600>,
			<6400 6200 6000 5800 5600 5400>,
			<5200 5000 4800 4600 4400 4200>,
			<4000 3800 3600 3400 3200 3000>,
			<2800 2600 2400 2200 2000 1800>,
			<1600 1400 1200 1000 900 800>,
			<700 600 500 400 300 200>,
			<100 0>;
		qcom,lut-data = <12992 15574 18336 19864 17742 19225>,
			<13995 16976 19246 19663 18642 19700>,
			<15507 18176 19745 18842 19179 19940>,
			<17137 19113 19937 17742 19445 19999>,
			<18492 19722 19922 16702 19528 19934>,
			<19181 19941 19802 16060 19511 19798>,
			<19375 19703 19205 15429 18680 19462>,
			<19483 19229 18255 14847 17558 19068>,
			<19443 18843 17697 15064 17225 18882>,
			<19207 18475 17331 16096 17081 18757>,
			<18959 18086 16946 16580 16921 18564>,
			<18737 17557 16356 16239 16509 17879>,
			<18545 17073 15773 15698 15996 17098>,
			<18841 17016 15568 15194 15553 16760>,
			<20563 17204 15473 14651 15126 16540>,
			<21680 17536 15448 14478 15045 16222>,
			<21207 19240 15589 14667 15620 15597>,
			<20365 21716 15942 14991 16206 15143>,
			<19760 22621 16945 15350 16267 15319>,
			<18693 23010 20129 15872 16205 15916>,
			<18068 23159 22653 16924 16617 16808>,
			<18738 23025 23590 20372 19019 18642>,
			<19586 22721 24177 23066 20771 20167>,
			<18824 22340 23969 22491 20436 20840>,
			<16176 21681 22431 21154 19701 21349>,
			<14085 20857 21428 20688 19150 21329>,
			<13230 19545 21871 20880 18704 20586>,
			<12654 18214 22560 21006 18222 19813>,
			<12535 18073 22594 20711 17485 18642>,
			<12592 18671 22072 20352 16829 17354>,
			<12682 19048 21733 20426 16851 17189>,
			<12805 17246 22283 20990 17381 17307>,
			<12960 14473 23195 21620 18091 17517>,
			<13063 14329 23531 22333 19173 19058>,
			<13131 16583 23660 22987 20435 20813>,
			<13208 18769 23667 23078 21554 20881>,
			<13382 19967 23486 22989 22633 20546>,
			<13588 20919 23134 22937 22901 20413>,
			<13681 21713 22534 22707 21398 20617>,
			<13799 22464 21317 22272 19908 21017>,
			<13865 22805 20500 21505 21435 22468>,
			<13644 18917 20457 20207 24303 24681>,
			<13384 14709 20441 20086 23126 23992>,
			<13294 14377 19741 20326 21951 23602>,
			<13018 14076 19488 20144 21723 19854>,
			<12724 13364 18942 20700 19847 21437>,
			<12793 13553 17758 19483 20446 19554>,
			<15341 13666 14440 20647 20058 18350>,
			<65535 13832 16203 20914 19237 17793>,
			<12492 13799 14739 20576 18347 16881>,
			<9660 18455 14253 20817 21542 19176>,
			<9936 9593 14317 21124 20613 17505>,
			<9312 11157 21522 20076 20847 19513>,
			<8881 10370 65535 18144 23469 20977>,
			<8881 10370 65535 18144 23469 20977>,
			<8881 10370 65535 18144 23469 20977>;
	};

	qcom,pc-temp-y6-lut {
		qcom,lut-col-legend = <(-10) 0 10 25 40 50>;
		qcom,lut-row-legend = <10000 9800 9600 9400 9200 9000>,
			<8800 8600 8400 8200 8000 7800>,
			<7600 7400 7200 7000 6800 6600>,
			<6400 6200 6000 5800 5600 5400>,
			<5200 5000 4800 4600 4400 4200>,
			<4000 3800 3600 3400 3200 3000>,
			<2800 2600 2400 2200 2000 1800>,
			<1600 1400 1200 1000 900 800>,
			<700 600 500 400 300 200>,
			<100 0>;
		qcom,lut-data = <5514 5236 5112 5032 5008 5001>,
			<5526 5243 5117 5032 5009 5002>,
			<5540 5249 5120 5033 5010 5003>,
			<5553 5253 5122 5034 5010 5004>,
			<5562 5256 5123 5034 5011 5005>,
			<5565 5257 5123 5035 5012 5006>,
			<5563 5255 5122 5036 5012 5007>,
			<5560 5252 5120 5036 5013 5007>,
			<5558 5251 5120 5037 5014 5008>,
			<5558 5250 5120 5039 5015 5009>,
			<5557 5250 5120 5041 5016 5010>,
			<5553 5251 5121 5043 5017 5011>,
			<5549 5254 5122 5045 5018 5012>,
			<5551 5257 5124 5047 5020 5013>,
			<5567 5264 5128 5049 5021 5014>,
			<5578 5271 5132 5052 5023 5016>,
			<5553 5276 5138 5056 5026 5018>,
			<5511 5280 5145 5061 5029 5019>,
			<5495 5278 5151 5068 5033 5023>,
			<5488 5259 5156 5077 5039 5028>,
			<5485 5240 5158 5079 5040 5029>,
			<5481 5226 5144 5067 5036 5026>,
			<5477 5215 5119 5052 5031 5023>,
			<5473 5209 5106 5043 5023 5016>,
			<5467 5204 5098 5035 5013 5008>,
			<5464 5202 5095 5034 5011 5007>,
			<5468 5200 5095 5034 5011 5007>,
			<5475 5199 5095 5035 5012 5007>,
			<5484 5199 5095 5037 5013 5008>,
			<5497 5200 5096 5038 5015 5010>,
			<5513 5202 5097 5040 5017 5012>,
			<5529 5203 5098 5043 5020 5014>,
			<5548 5206 5100 5045 5023 5016>,
			<5570 5211 5101 5047 5025 5019>,
			<5596 5222 5103 5048 5026 5021>,
			<5624 5236 5105 5048 5025 5019>,
			<5657 5251 5109 5044 5021 5013>,
			<5695 5270 5114 5042 5017 5010>,
			<5735 5290 5119 5041 5015 5010>,
			<5779 5315 5123 5041 5014 5011>,
			<5828 5339 5129 5042 5016 5013>,
			<5883 5358 5136 5045 5021 5018>,
			<5949 5380 5145 5045 5018 5014>,
			<6040 5418 5157 5045 5014 5009>,
			<6171 5473 5171 5043 5011 5006>,
			<6326 5531 5168 5049 5018 5017>,
			<6472 5595 5182 5055 5028 5027>,
			<6624 5688 5206 5066 5041 5039>,
			<6785 5842 5245 5079 5051 5049>,
			<7194 6132 5303 5081 5048 5041>,
			<8797 6483 5414 5075 5027 5022>,
			<12733 6858 5660 5081 5027 5022>,
			<13663 8146 6240 5108 5031 5026>,
			<32516 8442 6445 5211 5043 5034>,
			<32516 8442 6445 5211 5043 5034>,
			<32516 8442 6445 5211 5043 5034>;
	};

};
